# S32M24x register map
Vendor: NXP Semiconductors; File version: 1.3
CPU: CM4 r0p1, little endian, MPU, FPU, VTOR, 4 interrupt priority bits
Registers are 32-bit, read-write, reset 0x0 unless marked. A register's access mark holds for its fields unless they carry their own. Offsets are from the block's base; [hi:lo] are bit positions; {n}, {i} and the like mark numbered series; 'fields as' and 'values as' point back to an identical list.

## GDU_AE — GDU
Base 0x00000180
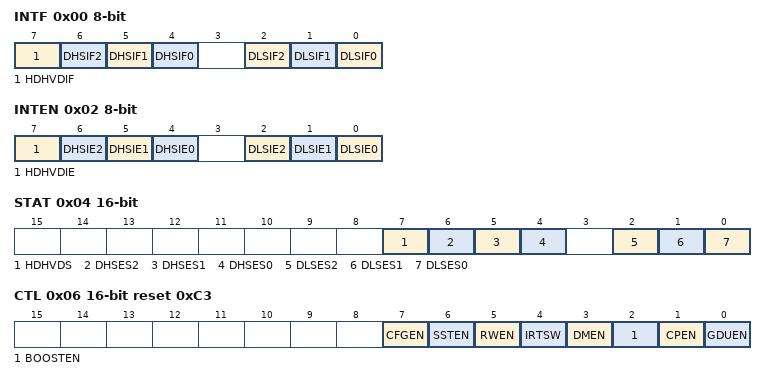
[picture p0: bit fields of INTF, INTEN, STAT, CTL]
0x00 INTF 8-bit write-1-clears — Interrupt Flag
  [7] HDHVDIF write-1-clears — HD High Voltage Detect Interrupt Flag
    0=BELOW (HD voltage below the threshold); 1=ABOVE (HD voltage above the threshold)
  [6] DHSIF2 write-1-clears — Desaturation High-Side 2 Interrupt Flag
    0=NOERROR; 1=ERROR
  [5] DHSIF1 write-1-clears — Desaturation High-Side 1 Interrupt Flag
    0=NOERROR; 1=ERROR
  [4] DHSIF0 write-1-clears — Desaturation High-Side 0 Interrupt Flag
    0=NOERROR; 1=ERROR
  [2] DLSIF2 write-1-clears — Desaturation Low-Side 2 Interrupt Flag
    0=NOERROR; 1=ERROR
  [1] DLSIF1 write-1-clears — Desaturation Low-Side 1 Interrupt Flag
    0=NOERROR; 1=ERROR
  [0] DLSIF0 write-1-clears — Desaturation Low-Side 0 Interrupt Flag
    0=NOERROR; 1=ERROR
0x02 INTEN 8-bit — Interrupt Enable
  [all] fields
    0=DISABLE (Disables); 1=ENABLE (Enables)
  [7] HDHVDIE — HD High Voltage Detect Interrupt Enable
  [6] DHSIE2 — Desaturation High-Side Interrupt Enable
  [5] DHSIE1 — Desaturation High-Side Interrupt Enable
  [4] DHSIE0 — Desaturation High-Side 0 Interrupt Enable
  [2] DLSIE2 — Desaturation Low-Side 2 Interrupt Enable
  [1] DLSIE1 — Desaturation Low-Side 1 Interrupt Enable
  [0] DLSIE0 — Desaturation Low-Side 0 Interrupt Enable
0x04 STAT 16-bit ro — Status
  [7] HDHVDS — HD High Voltage Detect Status
    values as INTF.HDHVDIF
  [6] DHSES2 — Desaturation High-Side 2 Error Status
    0=NOERROR; 1=ERROR
  [5] DHSES1 — Desaturation High-Side 1 Error Status
    0=NOERROR; 1=ERROR
  [4] DHSES0 — Desaturation High-Side 0 Error Status
    0=NOERROR; 1=ERROR
  [2] DLSES2 — Desaturation Low-Side 2 Error Status
    0=NOERROR; 1=ERROR
  [1] DLSES1 — Desaturation Low-Side 1 Error Status
    0=NOERROR; 1=ERROR
  [0] DLSES0 — Desaturation Low-Side 0 Error Status
    0=NOERROR; 1=ERROR
0x06 CTL 16-bit reset 0xC3 — Control
  [all] fields
    0=DISABLE (Disables); 1=ENABLE (Enables)
  [7] CFGEN — Configuration Enable
  [6] SSTEN — Safe State Enable
  [5] RWEN — Register Write Enable
  [4] IRTSW — Iref Trimming by Software
  [3] DMEN — Delay Measurement Enable
  [2] BOOSTEN — Boost Enable
  [1] CPEN — Charge Pump Enable
  [0] GDUEN — Gate Driver Unit Enable
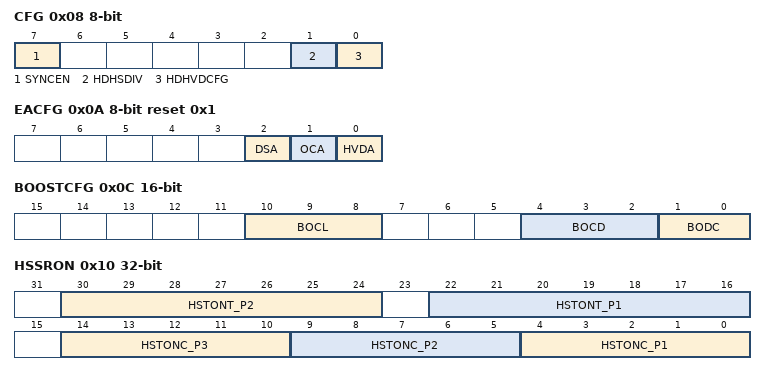
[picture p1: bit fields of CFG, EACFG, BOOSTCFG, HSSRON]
0x08 CFG 8-bit — Configuration
  [7] SYNCEN — Synchronization Enable
    0=DISABLE (Disables); 1=ENABLE (Enables)
  [1] HDHSDIV — HD and High-Side Divider
    0=LOW; 1=HIGH
  [0] HDHVDCFG — HD High Voltage Detect
    0=LOW (Low voltage); 1=HIGH (High voltage)
0x0A EACFG 8-bit reset 0x1 — Error Reaction
  [2] DSA — Desaturation Action
    0=DISABLE (Turn off only the desaturated FET.); 1=ENABLE (Turn off all FETs)
  [1] OCA — Overcurrent Action
    0=LOWON (Low-side gate drivers on); 1=LOWOFF (Low-side gate drivers off)
  [0] HVDA — High Voltage Detection Action
    0=LOWON (Turn on all low-side gate drivers); 1=LOWOFF (Turn off all low-side gate drivers)
0x0C BOOSTCFG 16-bit — Boost
  [10:8] BOCL — Boost Current Limit
  [4:2] BOCD — Boost Clock Divider
  [1:0] BODC — Boost Duty Cycle
    0=DUTY50 (50%); 1=DUTY25 (25%); 2=DUTY75 (75%)
0x0E BTCFG 16-bit — Blanking Time
  [8:0] BT — Blanking Time Adjustment
0x10 HSSRON — High-Side Slew Rate On
  [30:24] HSTONT_P2 — High-Side Turn On Time Point 2
  [22:16] HSTONT_P1 — High-Side Turn On Time Point 1
  [14:10] HSTONC_P3 — High-Side Turn On Current Time Point 3
  [9:5] HSTONC_P2 — High-Side Turn On Current Time Point 2
  [4:0] HSTONC_P1 — High-Side Turn On Current Time Point 1
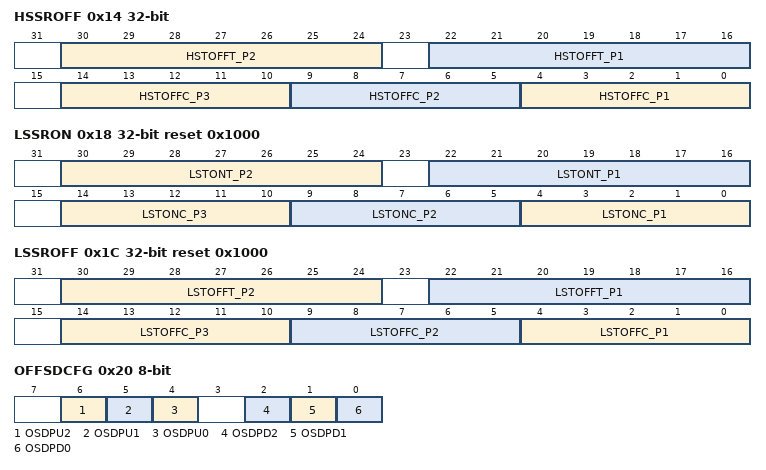
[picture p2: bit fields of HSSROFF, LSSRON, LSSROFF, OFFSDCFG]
0x14 HSSROFF — High-Side Slew Rate Off
  [30:24] HSTOFFT_P2 — High-Side Turn Off Time Point 2
  [22:16] HSTOFFT_P1 — High-Side Turn Off Time Point 1
  [14:10] HSTOFFC_P3 — High-Side Turn Off Current Time Point 3
  [9:5] HSTOFFC_P2 — High-Side Turn Off Current Time Point 2
  [4:0] HSTOFFC_P1 — High-Side Turn Off Current Time Point 1
0x18 LSSRON reset 0x1000 — Low-Side Slew Rate On
  [30:24] LSTONT_P2 — Low-Side Turn On Time Point 2
  [22:16] LSTONT_P1 — Low-Side Turn On Time Point 1
  [14:10] LSTONC_P3 — Low-Side Turn On Current Time Point 3
  [9:5] LSTONC_P2 — Low-Side Turn On Current Time Point 2
  [4:0] LSTONC_P1 — Low-Side Turn On Current Time Point 1
0x1C LSSROFF reset 0x1000 — Low-Side Slew Rate Off
  [30:24] LSTOFFT_P2 — Low-Side Turn On Time Point 2
  [22:16] LSTOFFT_P1 — Low-Side Turn Off Time Point 1
  [14:10] LSTOFFC_P3 — Low-Side Turn Off Current Time Point 3
  [9:5] LSTOFFC_P2 — Low-Side Turn Off Current Time Point 2
  [4:0] LSTOFFC_P1 — Low-Side Turn Off Current Time Point 1
0x20 OFFSDCFG 8-bit — Off-State Diagnostic
  [6] OSDPU2 — Off-State Diagnostic HS2 Pull Up
    0=NOTUP (Does not pull up); 1=UP (Pulls up)
  [5] OSDPU1 — Off-State Diagnostic HS1 Pull Up
    0=NOTUP (Does not pull up); 1=UP (Pulls up)
  [4] OSDPU0 — Off-State Diagnostic HS0 Pull Up
    0=NOTUP (Does not pull up); 1=UP (Pulls up)
  [2] OSDPD2 — Off-State Diagnostic HS2 Pull Down
    0=NOTDOWN (Does not pull down); 1=DOWN (Pulls down)
  [1] OSDPD1 — Off-State Diagnostic HS1 Pull Down
    0=NOTDOWN (Does not pull down); 1=DOWN (Pulls down)
  [0] OSDPD0 — Off-State Diagnostic HS0 Pull Down
    0=NOTDOWN (Does not pull down); 1=DOWN (Pulls down)
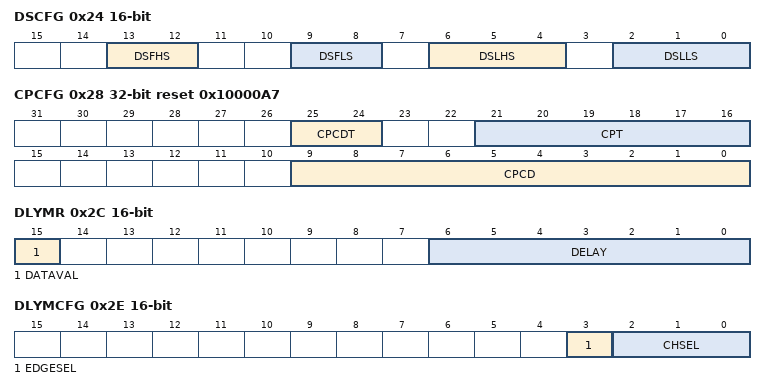
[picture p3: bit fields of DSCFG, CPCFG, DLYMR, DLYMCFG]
0x24 DSCFG 16-bit — Desaturation Level
  [13:12] DSFHS — Desaturation Filter High-Side
    0=V0 (200 ns); 1=V1 (600 ns); 2=V2 (1000 ns); 3=V3 (1400 ns)
  [9:8] DSFLS — Desaturation Filter Low-Side
    0=V0 (200 ns); 1=V1 (600 ns); 2=V2 (1000 ns); 3=V3 (1400 ns)
  [6:4] DSLHS — Desaturation Level High-Side
    0=V0 (0.15 V); 1=V1 (0.25 V); 2=V2 (0.35 V); 3=V3 (0.45 V); 4=V4 (0.7 V); 5=V5 (0.95 V); 6=V6 (1.2 V); 7=V7 (1.45 V)
  [2:0] DSLLS — Desaturation Level Low-Side
    values as DSLHS
0x28 CPCFG reset 0x10000A7 — Charge Pump
  [25:24] CPCDT — Charge Pump Charge Discharge Timing
    0=v0 (250 ns); 1=v1 (500 ns); 2=v2 (750 ns); 3=v3 (1 us)
  [21:16] CPT — Charge Pump VCP On switch Timing
  [9:0] CPCD — Charge Pump Clock Divider
0x2C DLYMR 16-bit ro — Delay Measurement Result
  [15] DATAVAL — Data Valid
  [6:0] DELAY
0x2E DLYMCFG 16-bit — Delay Measurement
  [3] EDGESEL — Edge Selection
    0=NEGEDGE; 1=POSEDGE
  [2:0] CHSEL — Channel Selection
    {v}=PWM{v} ({v}) (v=0..5)
0x30 SUPCFG 8-bit reset 0x1 — Startup Configuration
  [0] SUP — Startup
    0=ON; 1=OFF
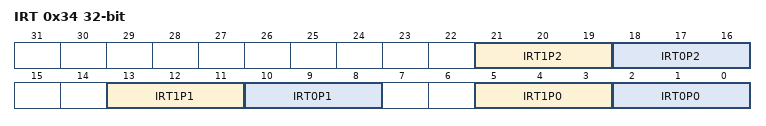
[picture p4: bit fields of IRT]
0x34 IRT — Iref Trimming
  [all] fields
    0=T0 (62.5% (minimum current)); 1=T1 (75%); 2=T2 (87.5%); 3=T3 (100% (10 uA at nominal process)); 4=T4 (112.5%); 5=T5 (125%); 6=T6 (137.5%); 7=T7 (150% (maximum current))
  [21:19] IRT1P2 — Iref Trimming HG2
  [18:16] IRT0P2 — Iref Trimming LG2
  [13:11] IRT1P1 — Iref Trimming HG1
  [10:8] IRT0P1 — Iref Trimming LG1
  [5:3] IRT1P0 — Iref Trimming HG0
  [2:0] IRT0P0 — Iref Trimming LG0
